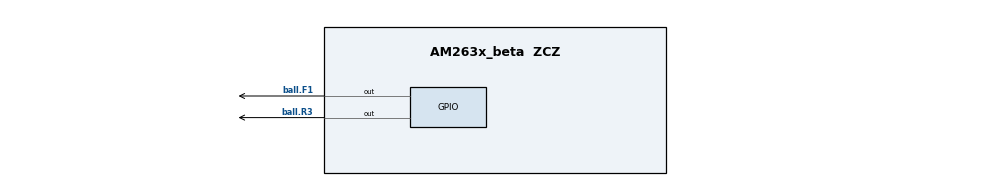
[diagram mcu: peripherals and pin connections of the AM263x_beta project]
/**
 * @cliArgs --device "AM263x_beta" --package "ZCZ" --part "AM263x" --context "r5fss0-0" --product "MCU_PLUS_SDK@07.03.01"
 * @versions {"tool":"1.12.1+2446"}
 */

/**
 * Import the modules used in this configuration.
 */
const eeprom     = scripting.addModule("/board/eeprom/eeprom", {}, false);
const eeprom1    = eeprom.addInstance();
const i2c        = scripting.addModule("/drivers/i2c/i2c", {}, false);
const i2c1       = i2c.addInstance();
const debug_log  = scripting.addModule("/kernel/dpl/debug_log");
const mpu_armv7  = scripting.addModule("/kernel/dpl/mpu_armv7", {}, false);
const mpu_armv71 = mpu_armv7.addInstance();
const mpu_armv72 = mpu_armv7.addInstance();
const mpu_armv73 = mpu_armv7.addInstance();
const mpu_armv74 = mpu_armv7.addInstance();
const mpu_armv75 = mpu_armv7.addInstance();
const enet_cpsw  = scripting.addModule("/networking/enet_cpsw/enet_cpsw", {}, false);
const enet_cpsw1 = enet_cpsw.addInstance();
const gpio       = scripting.addModule("/drivers/gpio/gpio", {}, false);
const gpio1      = gpio.addInstance();
const gpio58     = gpio.addInstance();

/**
 * Write custom configuration values to the imported modules.
 */
eeprom1.$name      = "CONFIG_EEPROM0";
eeprom1.i2cAddress = 0x53;

i2c1.$name               = "CONFIG_I2C0";
eeprom1.peripheralDriver = i2c1;
i2c1.I2C.$assign         = "I2C1";
i2c1.I2C.SCL.$assign     = "ball.D7";
i2c1.I2C.SDA.$assign     = "ball.C8";

gpio1.$name                = "CONFIG_GPIO1";
gpio1.pinDir               = "OUTPUT";
gpio1.GPIO.$assign         = "GPIO0";
gpio1.GPIO.gpioPin.$assign = "ball.R3";

gpio58.$name                = "CONFIG_GPIO58";
gpio58.pinDir               = "OUTPUT";
gpio58.GPIO.$assign         = "GPIO0";
gpio58.GPIO.gpioPin.$assign = "ball.F1";

debug_log.enableUartLog            = true;
debug_log.enableCssLog             = false;
debug_log.uartLog.$name            = "CONFIG_UART0";
debug_log.uartLog.UART.$assign     = "UART0";
debug_log.uartLog.UART.RXD.$assign = "ball.A7";
debug_log.uartLog.UART.TXD.$assign = "ball.A6";

mpu_armv71.$name             = "CONFIG_MPU_REGION0";
mpu_armv71.size              = 31;
mpu_armv71.attributes        = "Device";
mpu_armv71.accessPermissions = "Supervisor RD+WR, User RD";
mpu_armv71.allowExecute      = false;

mpu_armv72.$name             = "CONFIG_MPU_REGION1";
mpu_armv72.size              = 15;
mpu_armv72.accessPermissions = "Supervisor RD+WR, User RD";

mpu_armv73.$name             = "CONFIG_MPU_REGION2";
mpu_armv73.baseAddr          = 0x80000;
mpu_armv73.size              = 15;
mpu_armv73.accessPermissions = "Supervisor RD+WR, User RD";

mpu_armv74.$name             = "CONFIG_MPU_REGION3";
mpu_armv74.accessPermissions = "Supervisor RD+WR, User RD";
mpu_armv74.baseAddr          = 0x70000000;
mpu_armv74.size              = 21;

mpu_armv75.$name      = "CONFIG_MPU_REGION4";
mpu_armv75.baseAddr   = 0x70080000;
mpu_armv75.size       = 14;
mpu_armv75.attributes = "NonCached";

enet_cpsw1.$name                           = "CONFIG_ENET_CPSW0";
enet_cpsw1.phyAddr1                        = 3;
enet_cpsw1.phyAddr2                        = 12;
enet_cpsw1.PktPoolEnable                   = false;
enet_cpsw1.AppLinkUpPortMask               = "ALL_PORTS";
enet_cpsw1.DisableMacPort2                 = true;
enet_cpsw1.BoardType                       = "am263x-lp";
enet_cpsw1.txDmaChannel[0].$name           = "ENET_DMA_TX_CH0";
enet_cpsw1.rxDmaChannel[0].$name           = "ENET_DMA_RX_CH0";
enet_cpsw1.rxDmaChannel[0].PacketsCount    = 48;
enet_cpsw1.pinmux[0].$name                 = "ENET_CPSW_PINMUX0";
enet_cpsw1.pinmux[0].phyToMacInterfaceMode = "RGMII";
enet_cpsw1.pinmux[0].RGMII.$assign         = "RGMII1";
enet_cpsw1.pinmux[0].RGMII.RD0.$assign     = "ball.U17";
enet_cpsw1.pinmux[0].RGMII.RD1.$assign     = "ball.T17";
enet_cpsw1.pinmux[0].RGMII.RD2.$assign     = "ball.U18";
enet_cpsw1.pinmux[0].RGMII.RD3.$assign     = "ball.T18";
enet_cpsw1.pinmux[0].RGMII.RX_CTL.$assign  = "ball.R18";
enet_cpsw1.pinmux[0].RGMII.RXC.$assign     = "ball.R17";
enet_cpsw1.pinmux[0].RGMII.TD0.$assign     = "ball.P16";
enet_cpsw1.pinmux[0].RGMII.TD1.$assign     = "ball.P17";
enet_cpsw1.pinmux[0].RGMII.TD2.$assign     = "ball.P18";
enet_cpsw1.pinmux[0].RGMII.TD3.$assign     = "ball.N17";
enet_cpsw1.pinmux[0].RGMII.TX_CTL.$assign  = "ball.M18";
enet_cpsw1.pinmux[0].RGMII.TXC.$assign     = "ball.N18";
